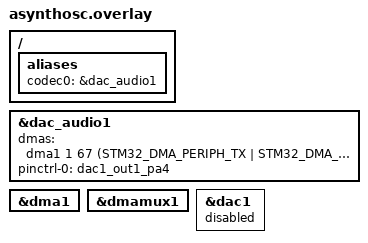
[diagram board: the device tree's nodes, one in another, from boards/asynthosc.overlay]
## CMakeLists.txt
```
# SPDX-License-Identifier: Apache-2.0

cmake_minimum_required(VERSION 3.20.0)

find_package(Zephyr REQUIRED HINTS $ENV{ZEPHYR_BASE})
project(dac_audio)

target_sources(app PRIVATE src/main.c)
```

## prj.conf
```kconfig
CONFIG_AUDIO=y
CONFIG_AUDIO_CODEC=y
CONFIG_AUDIO_CODEC_DAC_STM32=y
CONFIG_DMA=y
CONFIG_LOG=y
CONFIG_PRINTK=y
CONFIG_USE_DT_CODE_PARTITION=y
CONFIG_MAIN_STACK_SIZE=2048
CONFIG_FPU=y
CONFIG_FPU_SHARING=y
```

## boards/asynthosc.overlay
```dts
#include <zephyr/dt-bindings/dma/stm32_dma.h>

/ {
	aliases {
		codec0 = &dac_audio1;
	};
};

/*
 * Enable the DAC audio node defined in stm32h7.dtsi and wire it to the
 * board-specific DMA channel and PA4 analog output pin.
 *
 * DMA1 stream 1 (cell = 1; STM32H7 DMA offset = 1, so hardware stream 0).
 * DMAMUX1 request 67 = LL_DMAMUX1_REQ_DAC1_CH1.
 */
&dac_audio1 {
	dmas = <&dma1 1 67
		(STM32_DMA_PERIPH_TX | STM32_DMA_16BITS | STM32_DMA_PRIORITY_HIGH)
		0>;
	dma-names = "tx";
	pinctrl-0 = <&dac1_out1_pa4>;
	pinctrl-names = "default";
	status = "okay";
};

/* Enable DMA1 + DMAMUX1 so the STM32 DMA driver is compiled */
&dma1 {
	status = "okay";
};

&dmamux1 {
	status = "okay";
};

/* Hand DAC1 hardware to the audio driver; disable the plain DAC driver */
&dac1 {
	status = "disabled";
};
```

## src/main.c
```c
/*
 * DAC audio sample — 440 Hz sine wave via audio_codec_api.
 *
 * The driver is configured for 48 kHz.  A Q16.16 fixed-point phase
 * accumulator selects entries from a pre-computed 256-point sine table
 * scaled to the DAC's 12-bit full-scale range (0–4095, midpoint 2048).
 *
 * Audio flows entirely through DMA callbacks; main() sleeps forever after
 * priming the first buffer and starting the codec.
 */

#include <zephyr/kernel.h>
#include <zephyr/audio/codec.h>
#include <zephyr/logging/log.h>
#include <math.h>

#ifndef M_PI
#define M_PI 3.14159265358979323846
#endif

LOG_MODULE_REGISTER(dac_audio_sample, LOG_LEVEL_INF);

#define SAMPLE_RATE   48000U
#define BLOCK_SAMPLES 256U
#define BLOCK_BYTES   (BLOCK_SAMPLES * sizeof(uint16_t))

/* DDS phase step: freq × 2^32 / sample_rate; index = top 8 bits of accumulator */
#define FREQ_STEP_440HZ  ((uint32_t)((440ULL << 32) / SAMPLE_RATE))

static const struct device *codec_dev = DEVICE_DT_GET(DT_ALIAS(codec0));

/* Two alternating buffers; the callback fills whichever just completed */
static uint16_t audio_bufs[2][BLOCK_SAMPLES];
static uint8_t  active_buf;

/* Phase accumulator shared between fill calls (ISR-only, no lock needed) */
static uint32_t phase_acc;

static volatile uint32_t callback_count;

/* Sine table: 256 entries, 12-bit amplitude centred at 2048 */
static uint16_t sine_table[256];

/*
 * ~160 mV peak on 3.3 V DAC reference — instrument level for Focusrite
 * Scarlett Hi-Z input.  Full-scale (2047) would be ~1.65 V peak (+3.6 dBu),
 * roughly 18 dB too hot for a passive guitar jack.
 */
#define SINE_AMPLITUDE 200

static void build_sine_table(void)
{
	for (int i = 0; i < 256; i++) {
		sine_table[i] = (uint16_t)(2048.0 + SINE_AMPLITUDE * sin(2.0 * M_PI * i / 256.0));
	}
}

static void fill_buffer(uint16_t *buf)
{
	for (uint32_t i = 0; i < BLOCK_SAMPLES; i++) {
		uint8_t idx = (uint8_t)(phase_acc >> 24);
		buf[i] = sine_table[idx];
		phase_acc += FREQ_STEP_440HZ;
	}
}

static void tx_done(const struct device *dev, void *user_data)
{
	ARG_UNUSED(user_data);

	callback_count++;

	/* Toggle buffer and fill the one that just finished */
	active_buf ^= 1;
	fill_buffer(audio_bufs[active_buf]);
	audio_codec_write(dev, (uint8_t *)audio_bufs[active_buf], BLOCK_BYTES);
}

int main(void)
{
	struct audio_codec_cfg codec_cfg = {
		.mclk_freq = 0,
		.dai_type  = AUDIO_DAI_TYPE_PCM,
		.dai_route = AUDIO_ROUTE_PLAYBACK,
		.dai_cfg.pcm = {
			.dir          = AUDIO_DAI_DIR_TX,
			.pcm_width    = AUDIO_PCM_WIDTH_16_BITS,
			.channels     = 1,
			.block_size   = BLOCK_BYTES,
			.samplerate   = AUDIO_PCM_RATE_48K,
		},
	};
	int ret;

	if (!device_is_ready(codec_dev)) {
		LOG_ERR("codec device not ready");
		return -ENODEV;
	}

	build_sine_table();

	ret = audio_codec_configure(codec_dev, &codec_cfg);
	if (ret < 0) {
		LOG_ERR("audio_codec_configure failed: %d", ret);
		return ret;
	}

	ret = audio_codec_register_done_callback(codec_dev, tx_done, NULL, NULL, NULL);
	if (ret < 0) {
		LOG_ERR("audio_codec_register_done_callback failed: %d", ret);
		return ret;
	}

	/* Prime buffer 0 into DMA (transfer starts when start() enables the timer) */
	fill_buffer(audio_bufs[0]);
	active_buf = 0;

	ret = audio_codec_write(codec_dev, (uint8_t *)audio_bufs[0], BLOCK_BYTES);
	if (ret < 0) {
		LOG_ERR("audio_codec_write (prime) failed: %d", ret);
		return ret;
	}

	ret = audio_codec_start(codec_dev, AUDIO_DAI_DIR_TX);
	if (ret < 0) {
		LOG_ERR("audio_codec_start failed: %d", ret);
		return ret;
	}

	LOG_INF("440 Hz sine running at %u Hz on PA4", SAMPLE_RATE);

	/* Print DMA callback rate once per second — 48000/256 ≈ 187 cb/s expected */
	while (true) {
		k_sleep(K_SECONDS(1));
		LOG_INF("DMA callbacks/s: %u", callback_count);
		callback_count = 0;
	}

	return 0;
}
```
